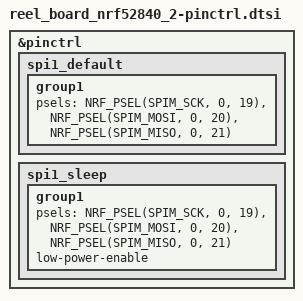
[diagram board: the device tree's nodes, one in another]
/*
 * Copyright (c) 2022 Nordic Semiconductor
 * SPDX-License-Identifier: Apache-2.0
 */

&pinctrl {
	spi1_default: spi1_default {
		group1 {
			psels = <NRF_PSEL(SPIM_SCK, 0, 19)>,
				<NRF_PSEL(SPIM_MOSI, 0, 20)>,
				<NRF_PSEL(SPIM_MISO, 0, 21)>;
		};
	};

	spi1_sleep: spi1_sleep {
		group1 {
			psels = <NRF_PSEL(SPIM_SCK, 0, 19)>,
				<NRF_PSEL(SPIM_MOSI, 0, 20)>,
				<NRF_PSEL(SPIM_MISO, 0, 21)>;
			low-power-enable;
		};
	};
};
